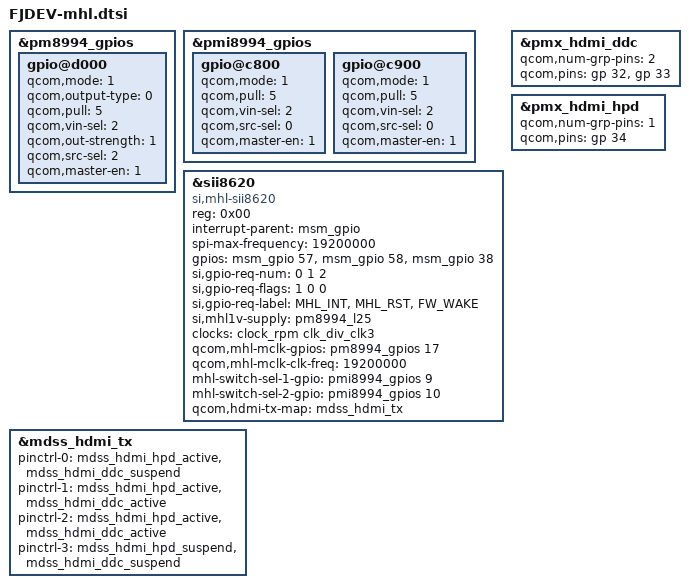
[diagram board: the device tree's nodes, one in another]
/*
 * FJDEV-mhl.dtsi
 *
 * COPYRIGHT(C) FUJITSU LIMITED 2014-2016
 *
 * This program is free software; you can redistribute it and/or
 * modify it under the terms of the GNU General Public License
 * as published by the Free Software Foundation; version 2
 * of the License.
 *
 * This program is distributed in the hope that it will be useful,
 * but WITHOUT ANY WARRANTY; without even the implied warranty of
 * MERCHANTABILITY or FITNESS FOR A PARTICULAR PURPOSE. See the
 * GNU General Public License for more details.
 *
 * You should have received a copy of the GNU General Public License
 * along with this program; if not, write to the Free Software
 * Foundation, Inc., 59 Temple Place - Suite 330, Boston, MA 02111-1307, USA.
 */

&pm8994_gpios {
	gpio@d000 { /* GPIO 17 */
		qcom,mode = <1>;
		qcom,output-type = <0>;
		qcom,pull = <5>;
		qcom,vin-sel = <2>;
		qcom,out-strength = <1>;
		qcom,src-sel = <2>;
		qcom,master-en = <1>;
		status = "okay";
	};
};

&pmi8994_gpios {
	gpio@c800 { /* GPIO 9 */
		qcom,mode = <1>;				/* Digital output */
		qcom,pull = <5>;                /* QPNP_PIN_PULL_NO */
		qcom,vin-sel = <2>;             /* QPNP_PIN_VIN2 */
		qcom,src-sel = <0>;             /* Constant */
		qcom,master-en = <1>;           /* ENABLE GPIO */
		status = "okay";
	};

	gpio@c900 { /* GPIO 10 */
		qcom,mode = <1>;				/* Digital output */
		qcom,pull = <5>;                /* QPNP_PIN_PULL_NO */
		qcom,vin-sel = <2>;             /* QPNP_PIN_VIN2 */
		qcom,src-sel = <0>;             /* Constant */
		qcom,master-en = <1>;           /* ENABLE GPIO */
		status = "okay";
	};
};

&sii8620 {
	compatible = "si,mhl-sii8620";
	reg = <0x00>;
	interrupt-parent  = <&msm_gpio>;
	spi-max-frequency = <19200000>;
	gpios =
		<&msm_gpio 57 0>,			/* MHL_INT */
		<&msm_gpio 58 0>,			/* MHL_RST */
		<&msm_gpio 38 0>;			/* FW_WAKE */
	si,gpio-req-num   = <0 1 2>;
	si,gpio-req-flags = <1 0 0>;	/* GPIOF_IN:1, GPIOF_OUT_INIT_LOW:0, GPIOF_OUT_INIT_LOW:0 */
	si,gpio-req-label = "MHL_INT", "MHL_RST", "FW_WAKE";
	si,mhl1v-supply = <&pm8994_l25>;

	clock-names = "mhl_clk";
	clocks = <&clock_rpm clk_div_clk3>;
	qcom,mhl-mclk-gpios    = <&pm8994_gpios 17 0>;
	qcom,mhl-mclk-clk-freq = <19200000>;

	mhl-switch-sel-1-gpio = <&pmi8994_gpios 9 0>;
	mhl-switch-sel-2-gpio = <&pmi8994_gpios 10 0>;

	qcom,hdmi-tx-map  = <&mdss_hdmi_tx>;

};

&pmx_hdmi_ddc {
	qcom,num-grp-pins = <2>;
	qcom,pins = <&gp 32>, <&gp 33>;
};

&pmx_hdmi_hpd {
	qcom,num-grp-pins = <1>;
	qcom,pins = <&gp 34>;
};

&mdss_hdmi_tx {
	pinctrl-names = "hdmi_hpd_active", "hdmi_ddc_active",
					"hdmi_active", "hdmi_sleep";
	pinctrl-0 = <&mdss_hdmi_hpd_active &mdss_hdmi_ddc_suspend>;
	pinctrl-1 = <&mdss_hdmi_hpd_active &mdss_hdmi_ddc_active>;
	pinctrl-2 = <&mdss_hdmi_hpd_active &mdss_hdmi_ddc_active>;
	pinctrl-3 = <&mdss_hdmi_hpd_suspend &mdss_hdmi_ddc_suspend>;
	status = "ok";
};

